# MM32F013x register map
File version: 1.01
CPU: CM0 r0p0, little endian, no MPU, no FPU, 2 interrupt priority bits
Registers are 32-bit, read-write, reset 0x0 unless marked. A register's access mark holds for its fields unless they carry their own. Offsets are from the block's base; [hi:lo] are bit positions; {n}, {i} and the like mark numbered series.

## USB — Universal serial bus full-speed device interface
Base 0x40005C00
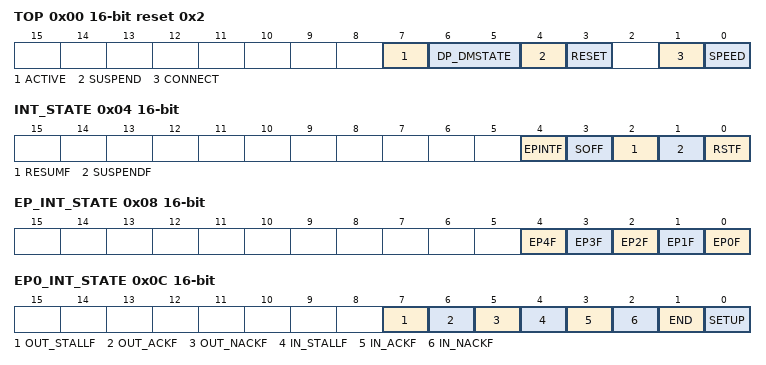
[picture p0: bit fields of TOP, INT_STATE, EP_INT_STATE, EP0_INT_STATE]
0x00 TOP 16-bit reset 0x2 — USB_TOP
  [7] ACTIVE — USB bus is active
  [6:5] DP_DMSTATE — Current USB DP/DM line state
  [4] SUSPEND — USB suspend state
  [3] RESET — Reset EP and FIFO in USB controller
  [1] CONNECT — USB connection
  [0] SPEED
0x04 INT_STATE 16-bit — interrupt state register
  [4] EPINTF — EP interrupt received
  [3] SOFF — BUS received
  [2] RESUMF — BUS resume received
  [1] SUSPENDF — BUS suspend received
  [0] RSTF — BUS reset received
0x08 EP_INT_STATE 16-bit ro — EP interrupt state register
  [n] EP{n}F (n=0..4) — EP{n} interrupt received
0x0C EP0_INT_STATE 16-bit — EP0 interrupt state register
  [7] OUT_STALLF — OUT-STALL received
  [6] OUT_ACKF — OUT-ACK received
  [5] OUT_NACKF — OUT-NACK received
  [4] IN_STALLF — IN-STALL received
  [3] IN_ACKF — IN-ACK received
  [2] IN_NACKF — IN-NACK received
  [1] END — Status stage finished
  [0] SETUP — SETUP packet received
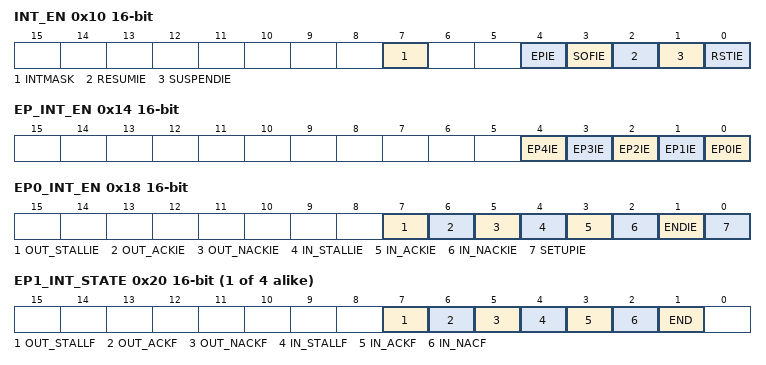
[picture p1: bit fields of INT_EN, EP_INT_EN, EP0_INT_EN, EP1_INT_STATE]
0x10 INT_EN 16-bit — interrupt enable register
  [7] INTMASK — interrupt mask
  [4] EPIE — EP interrupt enable
  [3] SOFIE — SOF interrupt enable
  [2] RESUMIE — BUS resume interrupt enable
  [1] SUSPENDIE — BUS suspend interrupt enable
  [0] RSTIE — BUS reset interrupt enable
0x14 EP_INT_EN 16-bit — EP interrupt enable register
  [n] EP{n}IE (n=0..4) — EP{n} interrupt enable
0x18 EP0_INT_EN 16-bit — EP0 interrupt enable register
  [7] OUT_STALLIE — OUT-STALL interrupt enable
  [6] OUT_ACKIE — OUT-ACK interrupt enable
  [5] OUT_NACKIE — OUT-NACK interrupt enable
  [4] IN_STALLIE — IN-STALL interrupt enable
  [3] IN_ACKIE — IN-ACK interrupt enable
  [2] IN_NACKIE — IN-NACK interrupt enable
  [1] ENDIE — Status stage finished interrupt enable
  [0] SETUPIE — SETUP packet interrupt enable
{0x1C+4i} EP{i}_INT_STATE 16-bit (i=1..4) — EP{i} interrupt state register
  [7] OUT_STALLF — OUT-STALL received
  [6] OUT_ACKF — OUT-ACK received
  [5] OUT_NACKF — OUT-NACK received
  [4] IN_STALLF — IN-STALL received
  [3] IN_ACKF — IN-ACK received
  [2] IN_NACF — IN-NACK received
  [1] END — Status stage finished
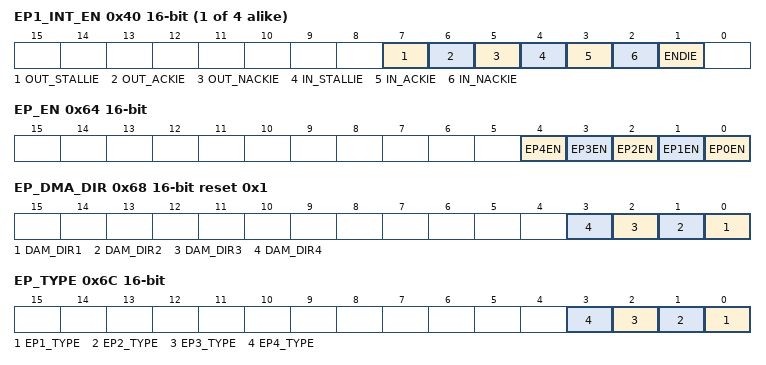
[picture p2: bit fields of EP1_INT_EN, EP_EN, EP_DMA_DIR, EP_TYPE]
{0x3C+4i} EP{i}_INT_EN 16-bit (i=1..4) — EP{i} interrupt enable register
  [7] OUT_STALLIE — OUT-STALL interrupt enable
  [6] OUT_ACKIE — OUT-ACK interrupt enable
  [5] OUT_NACKIE — OUT-NACK interrupt enable
  [4] IN_STALLIE — IN-STALL interrupt enable
  [3] IN_ACKIE — IN-ACK interrupt enable
  [2] IN_NACKIE — IN-NACK interrupt enable
  [1] ENDIE — Status stage finished interrupt enable
0x60 ADDR 16-bit — USB address
  [6:0] ADDR
0x64 EP_EN 16-bit — EP Enable End
  [n] EP{n}EN (n=0..4) — Enable End Point {n}
0x68 EP_DMA_DIR 16-bit reset 0x1 — DMA End-point direction register
  [n-1] DAM_DIR{n} (n=1..4) — Point {n} Dma Dir
0x6C EP_TYPE 16-bit — Endpoint type register
  [n-1] EP{n}_TYPE (n=1..4) — Point {n} type
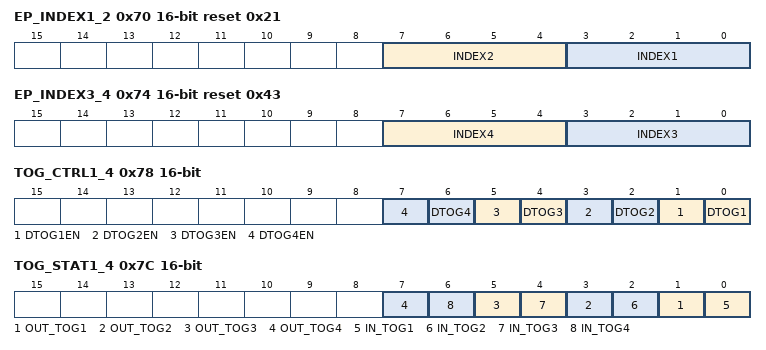
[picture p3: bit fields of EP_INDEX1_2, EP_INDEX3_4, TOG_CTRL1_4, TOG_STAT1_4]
0x70 EP_INDEX1_2 16-bit reset 0x21 — End-point index register 1_2
  [7:4] INDEX2 — Point 2 index
  [3:0] INDEX1 — Point 1 index
0x74 EP_INDEX3_4 16-bit reset 0x43 — End-point index register 3_4
  [7:4] INDEX4 — Point 4 index
  [3:0] INDEX3 — Point 3 index
0x78 TOG_CTRL1_4 16-bit
  [2n-1] DTOG{n}EN (n=1..4) — Set End Point {n} enable
  [2n-2] DTOG{n} (n=1..4) — Set End Point {n} Toggle
0x7C TOG_STAT1_4 16-bit
  [2n-1] OUT_TOG{n} (n=1..4) — End Point {n} Toggle ON State
  [2n-2] IN_TOG{n} (n=1..4) — End Point {n} Toggle IN State
{0x80+4i} SETUP{i} 16-bit ro (i=0..7) — Setup Date {i} register
  [7:0] SETUPD{i} — Setup Data {i}
0xA0 PACKET_SIZEL 16-bit reset 0x40
  [7:0] SIZE0 — USB Max Packet Size
0xA4 PACKET_SIZEH reset 0x40
  [7:0] SIZE1 — USB Max Packet Size
{0x100+4i} EP{i}_AVAIL 16-bit ro (i=0..4)
  [7:0] EP{i}AVIL — EP{i} FIFO available data number
{0x120+4i} DAM_ADDR{i} 16-bit ro (i=0..3) — DMA1 ADDR{i} register
  [7:0] DMA_ADDR{i} — USB DAM address{i}[{8i+7}:{8i}]
0x130 DMA_NUML 16-bit
  [7:0] DMA_NUML — EP2 DMA number 0-7
0x134 DMA_NUMH 16-bit
  [7:0] DMA1_NUMH — EP2 DMA number 8-15
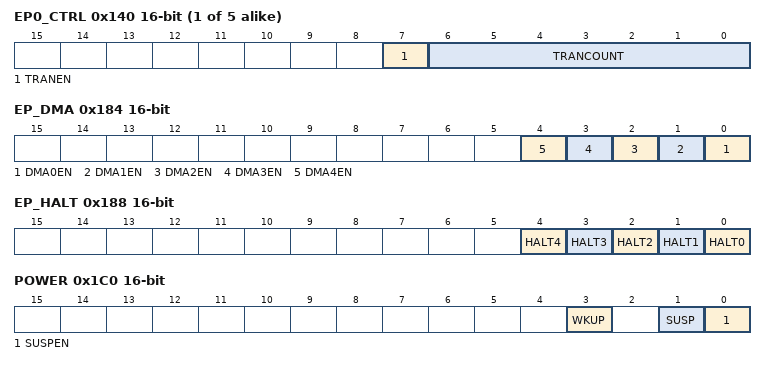
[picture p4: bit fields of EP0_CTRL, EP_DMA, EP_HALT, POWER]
{0x140+4i} EP{i}_CTRL 16-bit (i=0..4)
  [7] TRANEN — EP{i} transfer enable
  [6:0] TRANCOUNT — EP{i} transfer counter
{0x160+4i} EP{i}_FIFO 16-bit (i=0..4)
  [7:0] EP{i}_FIFO — EP{i} FIFO port
0x180 EP_MEM 16-bit
  [2:0] EP_MEM — EP memory
0x184 EP_DMA 16-bit
  [n] DMA{n}EN (n=0..4) — EP{n} DMA enable
0x188 EP_HALT 16-bit
  [n] HALT{n} (n=0..4) — EP{n} halt
0x1C0 POWER 16-bit — Power control register
  [3] WKUP — Enable controller wake up from suspend state
  [1] SUSP — suspend
  [0] SUSPEN — BUS suspend enable bit
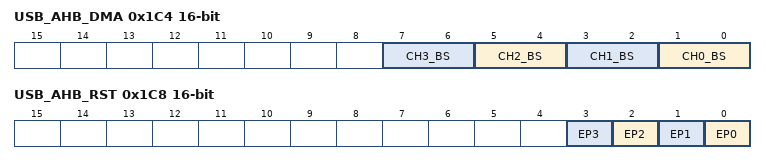
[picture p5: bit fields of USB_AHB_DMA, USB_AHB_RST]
0x1C4 USB_AHB_DMA 16-bit
  [2n+1:2n] CH{n}_BS (n=0..3) — Channel {n} burst set
0x1C8 USB_AHB_RST 16-bit
  [n] EP{n} (n=0..3) — Endpoint {n} reset
